# STM32WL5x_CM0P register map
File version: 1.5
CPU: CM0 r0p1, little endian, MPU, no FPU, 4 interrupt priority bits
Registers are 32-bit, read-write, reset 0x0 unless marked. A register's access mark holds for its fields unless they carry their own. Offsets are from the block's base; [hi:lo] are bit positions; {n}, {i} and the like mark numbered series.

## GPIOH — General-purpose I/Os
Base 0x48001C00
0x00 MODER reset 0xC0 — GPIO port mode register
  [7:6] MODER3 — Port x configuration bits (y = 0..15)
0x04 OTYPER — GPIO port output type register
  [3] OT3 — Port x configuration bits (y = 0..15)
0x08 OSPEEDR — GPIO port output speed register
  [7:6] OSPEEDR3 — Port x configuration bits (y = 0..15)
0x0C PUPDR — GPIO port pull-up/pull-down register
  [7:6] PUPDR3 — Port x configuration bits (y = 0..15)
0x10 IDR ro — GPIO port input data register
  [3] IDR3 — Port input data (y = 0..15)
0x14 ODR — GPIO port output data register
  [3] ODR3 — Port output data (y = 0..15)
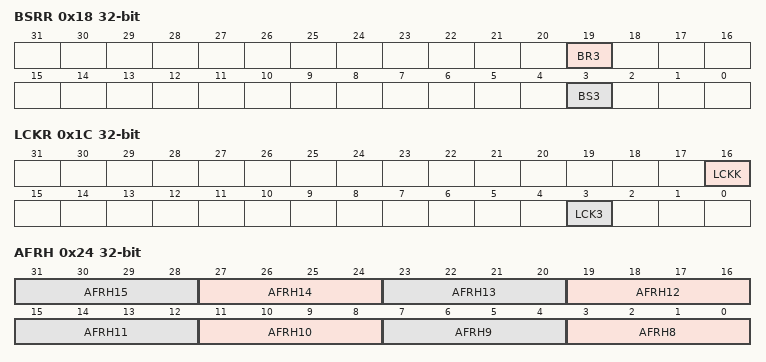
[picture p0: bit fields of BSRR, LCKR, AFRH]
0x18 BSRR wo — GPIO port bit set/reset register
  [19] BR3 — Port x reset bit y (y = 0..15)
  [3] BS3 — Port x set bit y (y= 0..15)
0x1C LCKR — GPIO port configuration lock register
  [16] LCKK — Port x lock bit y (y= 0..15)
  [3] LCK3 — Port x lock bit y (y= 0..15)
0x20 AFRL — GPIO alternate function low register
  [15:12] AFRL3 — Alternate function selection for port x bit y (y = 0..7)
0x24 AFRH — GPIO alternate function high register
  [4n-29:4n-32] AFRH{n} (n=8..15) — Alternate function selection for port x bit y (y = 8..15)
0x28 BRR — GPIO port bit reset register
  [3] BR3 — Port Reset bit

## EXTI — External interrupt/event controller
Base 0x58000800
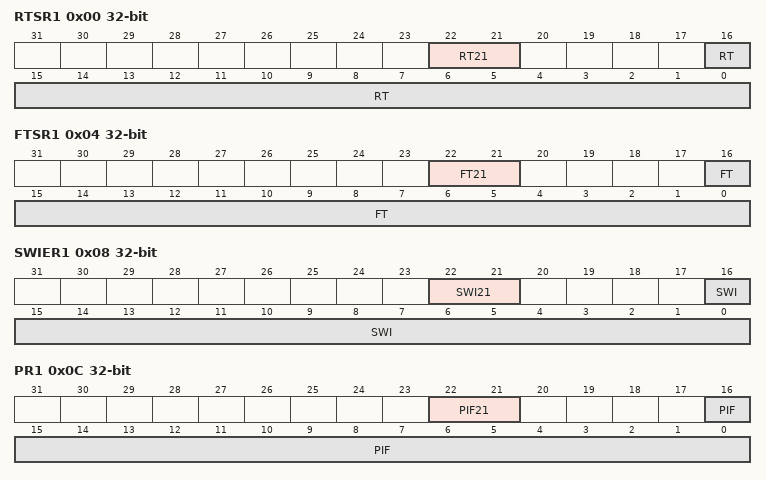
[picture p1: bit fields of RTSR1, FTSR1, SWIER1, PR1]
0x00 RTSR1 — rising trigger selection register
  [22:21] RT21 — Rising trigger event configuration bit of Configurable Event input
  [16:0] RT — Rising trigger event configuration bit of Configurable Event input
0x04 FTSR1 — falling trigger selection register
  [22:21] FT21 — Falling trigger event configuration bit of Configurable Event input
  [16:0] FT — Falling trigger event configuration bit of Configurable Event input
0x08 SWIER1 — software interrupt event register
  [22:21] SWI21 — Software interrupt on event
  [16:0] SWI — Software interrupt on event
0x0C PR1 — EXTI pending register
  [22:21] PIF21 — Configurable event inputs Pending bit
  [16:0] PIF — Configurable event inputs Pending bit
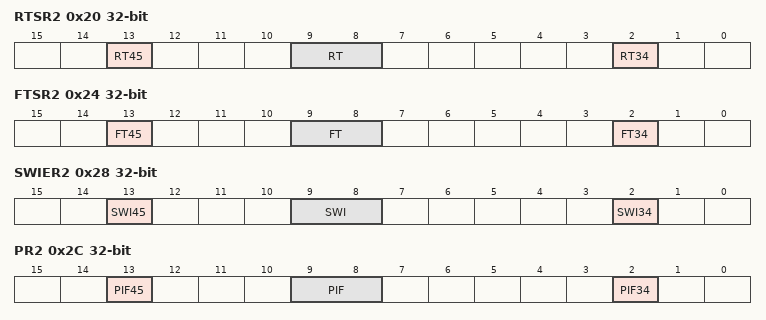
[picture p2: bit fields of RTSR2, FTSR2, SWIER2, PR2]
0x20 RTSR2 — rising trigger selection register
  [13] RT45 — Rising trigger event configuration bit of Configurable Event input
  [9:8] RT — Rising trigger event configuration bit of Configurable Event input
  [2] RT34 — Rising trigger event configuration bit of Configurable Event input
0x24 FTSR2 — falling trigger selection register
  [13] FT45 — Falling trigger event configuration bit of Configurable Event input
  [9:8] FT — Falling trigger event configuration bit of Configurable Event input
  [2] FT34 — Falling trigger event configuration bit of Configurable Event input
0x28 SWIER2 — software interrupt event register
  [13] SWI45 — Software interrupt on event 45
  [9:8] SWI — Software interrupt on event
  [2] SWI34 — Software interrupt on event
0x2C PR2 — pending register
  [13] PIF45 — Configurable event inputs 45 Pending bit.
  [9:8] PIF — Configurable event inputs 40_41 Pending bit.
  [2] PIF34 — Configurable event inputs 33 Pending bit.
0x80 CmIMR1 — CPUm wakeup with interrupt mask register
  [31:0] IM — CPU(m) wakeup with interrupt Mask on Event input
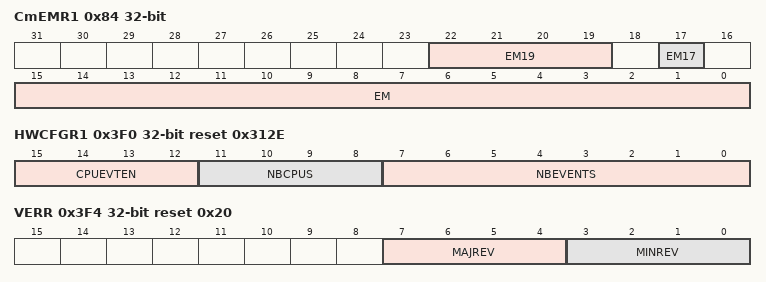
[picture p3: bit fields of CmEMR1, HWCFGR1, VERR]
0x84 CmEMR1 — CPUm wakeup with event mask register
  [22:19] EM19 — CPU(m) wakeup with event generation mask on event input
  [17] EM17 — CPU(m) Wakeup with event generation Mask on Event input
  [15:0] EM — CPU(m) Wakeup with event generation Mask on Event input
0x90 CmIMR2 — CPUm wakeup with interrupt mask register
  [14:0] IM — CPUm Wakeup with interrupt Mask on Event input
0x94 CmEMR2 — CPUm wakeup with event mask register
  [9:8] EM — CPU(m) Wakeup with event generation Mask on Event input
0x3D8 HWCFGR7 ro — EXTI Hardware configuration registers
  [31:0] CPUEVENT — HW configuration CPU event generation
0x3DC HWCFGR6 ro reset 0x300 — Hardware configuration registers
  [31:0] CPUEVENT — HW configuration CPU event generation
0x3E0 HWCFGR5 ro reset 0x7AFFFF — Hardware configuration registers
  [31:0] CPUEVENT — HW configuration CPU event generation
0x3E4 HWCFGR4 ro — Hardware configuration registers
  [31:0] EVENT_TRG — HW configuration event trigger type
0x3E8 HWCFGR3 ro reset 0x2304 — Hardware configuration registers
  [31:0] EVENT_TRG — HW configuration event trigger type
0x3EC HWCFGR2 ro reset 0x61FFFF — Hardware configuration registers
  [31:0] EVENT_TRG — HW configuration event trigger type
0x3F0 HWCFGR1 ro reset 0x312E — Hardware configuration register 1
  [15:12] CPUEVTEN — HW configuration of CPU(m) event output enable
  [11:8] NBCPUS — HW configuration number of CPUs
  [7:0] NBEVENTS — HW configuration number of event
0x3F4 VERR ro reset 0x20 — EXTI IP Version register
  [7:4] MAJREV — Major Revision number
  [3:0] MINREV — Minor Revision number
0x3F8 IPIDR ro reset 0xE0001 — Identification register
  [31:0] ID — IP Identification
0x3FC SIDR ro reset 0xA3C5DD01 — Size ID register
  [31:0] SID — Size Identification
